# CEC1734_S0_2HW device description
Architecture: CORTEX-M4; Family: CEC173X; Series: CEC
Registers are 32-bit, read-write, reset 0x0 unless marked. A register's access mark holds for its fields unless they carry their own. Offsets are from the block's base; [hi:lo] are bit positions.

## PCR — The Power, Clocks, and Resets (PCR) Section identifies clock sources, and reset inputs to the chip.
Instances: PCR 0x40080100
0x04 PROC_CLK_CTRL reset 0x4 — Processor Clock Control Register [7:0] Processor Clock Divide Value (PROC_DIV)
  [7:0] DIV — Selects the EC clock rate
    1=DIVIDE_BY_1 (Divide 96 MHz clock by 1 (96 MHz Processor Clock)); 2=DIVIDE_BY_2 (Divide 96 MHz clock by 2 (48 MHz Processor Clock)); 4=DIVIDE_BY_4 (Divide 96 MHz clock by 4 (24 MHz Processor Clock)); 16=DIVIDE_BY_16 (Divide 96 MHz clock by 16 (6 MHz Processor Clock)); 48=DIVIDE_BY_48 (Divide 96 MHz clock by 48 (2 MHz Processor Clock))
0x08 SLOW_CLK_CTRL reset 0x1E0 — Configures the EC_CLK clock domain
  [9:0] DIV — SLOW_CLOCK_DIVIDE. n=Divide by n; 0=Clock off
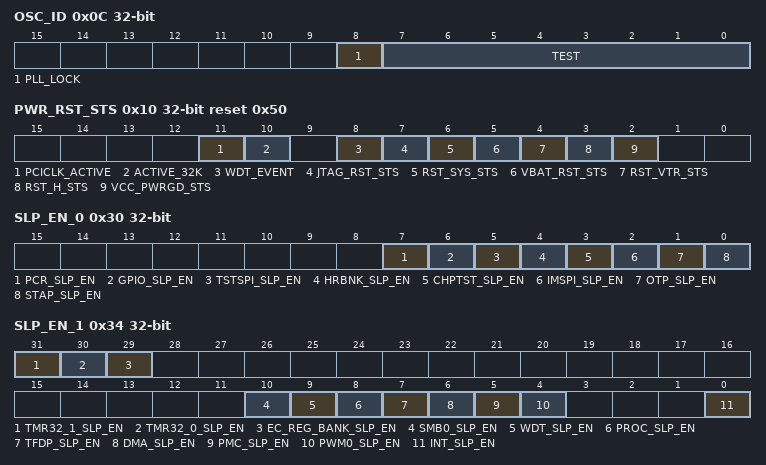
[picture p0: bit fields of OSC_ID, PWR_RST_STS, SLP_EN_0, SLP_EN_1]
0x0C OSC_ID — Oscillator ID Register
  [8] PLL_LOCK — PLL Lock Status
  [7:0] TEST — Test bits
0x10 PWR_RST_STS reset 0x50 — PCR Power Reset Status Register
  [11] PCICLK_ACTIVE — PCICLK_ACTIVE (PCICLK_ACTIVE)
  [10] ACTIVE_32K — 32K ACTIVE (ACTIVE_32K)
  [8] WDT_EVENT — Indicates that a WDT_EVENT happened. (R/W1C) 0 = Not active. 1 = A WDT_EVENT occured.
  [7] JTAG_RST_STS — Indicates status of JTAG_TRST# pin. 0 = No JTAG reset occurred since the last time this bit was cleared. 1 = A reset occurred because of a JTAG command.
  [6] RST_SYS_STS — Indicates the status of RESET_SYS.(R/W1C) 0 = No reset occurred since the last time this bit was cleared. 1 = A reset occurred.
  [5] VBAT_RST_STS — VBAT reset status 0 = No reset occurred while VTR was off or since the last time this bit was cleared. 1 = A reset occurred.(R/WC)
  [4] RST_VTR_STS — Indicates the status of RESET_VTR. 0 = reset active. 1 = reset not active.(R/W1C)
  [3] RST_H_STS — Indicates the status of RESET_VCC. 0 = reset active. 1 = reset not active.
  [2] VCC_PWRGD_STS — Indicates the status of VCC_PWRGD. 0 = PWRGD not asserted. 1 = PWRGD asserte.
0x18 SYS_RST — System Reset Register
  [8] SOFT_SYS_RST — A write of a 1 forces an assertion of the RESET_SYS reset signal, resetting the device. A write of 0 has no effect.
0x24 PRIV_EN_LOCK — Peripheral Privilege Register
  [0] LOCK_EN — Peripheral Privilege Lock Register. 1=Locked, 0=Unlocked. Locks Itself and CHIP_PRIV_EN, EC_PRIV_EN, EC_PRIV_EN2, EC_PRIV_EN3, HOST_PRIV_EN registers
0x30 SLP_EN_0 — Sleep Enable 0 Register
  [7] PCR_SLP_EN — PCR Sleep Enable
  [6] GPIO_SLP_EN — GPIO Sleep Enable
  [5] TSTSPI_SLP_EN — Test SPI Sleep Enable
  [4] HRBNK_SLP_EN — Host Register Bank Sleep Enable
  [3] CHPTST_SLP_EN — Chip Test Sleep Enable
  [2] IMSPI_SLP_EN — IMSPI Sleep Enable
  [1] OTP_SLP_EN — OTP Sleep Enable
  [0] STAP_SLP_EN — STAP Sleep Enable
0x34 SLP_EN_1 — Sleep Enable 1 Register
  [31] TMR32_1_SLP_EN — TIMER32_1 Sleep Enable (TIMER32_1_SLP_EN)
  [30] TMR32_0_SLP_EN — TIMER32_0 Sleep Enable (TIMER32_0_SLP_EN)
  [29] EC_REG_BANK_SLP_EN — EC Register Bank Sleep Enable (EC_REG_BANK_SLP_EN)
  [10] SMB0_SLP_EN — SMB0 Sleep Enable (SMB0_SLP_EN)
  [9] WDT_SLP_EN — Watch Dog Sleep Enable (WDT_SLP_EN)
  [8] PROC_SLP_EN — PROCESSOR Sleep Enable (PROCESSOR_SLP_EN)
  [7] TFDP_SLP_EN — TFDP Sleep Enable (TFDP_SLP_EN)
  [6] DMA_SLP_EN — DMA Sleep Enable (DMA_SLP_EN)
  [5] PMC_SLP_EN — PMC Sleep Enable (PMC_SLP_EN)
  [4] PWM0_SLP_EN — PWM0 Sleep Enable (PWM0_SLP_EN)
  [0] INT_SLP_EN — Interrupt Sleep Enable
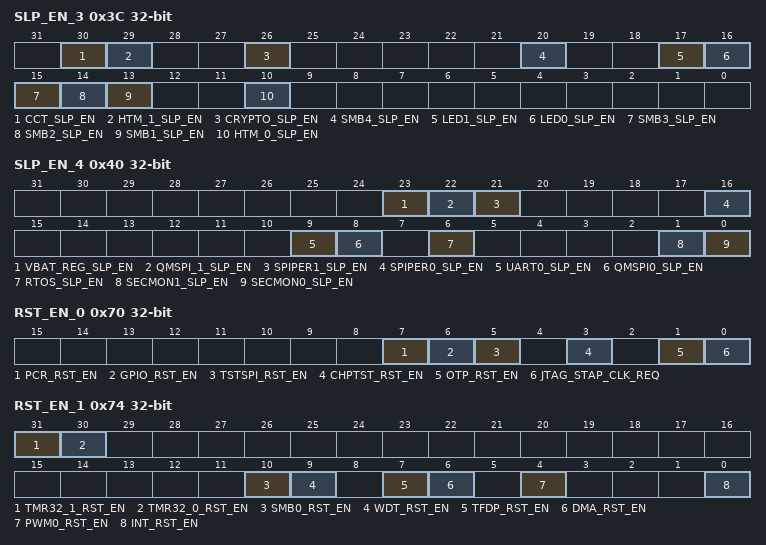
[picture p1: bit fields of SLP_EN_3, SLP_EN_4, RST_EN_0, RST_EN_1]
0x3C SLP_EN_3 — Sleep Enable 3 Register
  [30] CCT_SLP_EN — Capture Compare Timer Sleep Enable (CCTIMER_SLP_EN)
  [29] HTM_1_SLP_EN — Hibernation TIMER 1 Sleep Enable (HTM_1_SLP_EN)
  [26] CRYPTO_SLP_EN — CRYPTO Sleep Enable
  [20] SMB4_SLP_EN — SMB4 Sleep Enable (SMB4_SLP_EN)
  [17] LED1_SLP_EN — LED1 Sleep Enable (LED1_SLP_EN)
  [16] LED0_SLP_EN — LED0 Sleep Enable (LED0_SLP_EN)
  [15] SMB3_SLP_EN — SMB3 Sleep Enable (SMB3_SLP_EN)
  [14] SMB2_SLP_EN — SMB2 Sleep Enable (SMB2_SLP_EN)
  [13] SMB1_SLP_EN — SMB1 Sleep Enable (SMB1_SLP_EN)
  [10] HTM_0_SLP_EN — Hibernation Timer 0 Sleep Enable (HTM_0_SLP_EN)
0x40 SLP_EN_4 — Sleep Enable 4 Register
  [23] VBAT_REG_SLP_EN — VBAT REG Sleep Enable (VBAT_REG_SLP_EN)
  [22] QMSPI_1_SLP_EN — QMSPI 1 Sleep Enable (QMSPI_1_SLP_EN)
  [21] SPIPER1_SLP_EN — SPI Peropheral 1 Sleep Enable (SPIPER1_SLP_EN)
  [16] SPIPER0_SLP_EN — SPI Peropheral 0 Sleep Enable (SPIPER0_SLP_EN)
  [9] UART0_SLP_EN — UART0 Sleep Enable (UART_1_SLP_EN)
  [8] QMSPI0_SLP_EN — Quad Master SPI 0 Sleep Enable (QMSPI_1_SLP_EN)
  [6] RTOS_SLP_EN — RTOS Sleep Enable (RTOS_SLP_EN)
  [1] SECMON1_SLP_EN — SPI Monitor 1 Sleep Enable (SECMON1_SLP_EN)
  [0] SECMON0_SLP_EN — SPI Monitor 0 Sleep Enable (SECMON0_SLP_EN)
0x70 RST_EN_0 — Reset Enable 0 Register
  [7] PCR_RST_EN — PCR Reset Enable
  [6] GPIO_RST_EN — GPIO Reset Enable
  [5] TSTSPI_RST_EN — Test SPI Reset Enable
  [3] CHPTST_RST_EN — Chip Test Reset Enable
  [1] OTP_RST_EN — OTP Reset Enable
  [0] JTAG_STAP_CLK_REQ — JTAG STAP Enable
0x74 RST_EN_1 — Reset Enable 1 Register
  [31] TMR32_1_RST_EN — TIMER32_1 Reset Enable (TIMER32_1_RST_EN)
  [30] TMR32_0_RST_EN — TIMER32_0 Reset Enable (TIMER32_0_RST_EN)
  [10] SMB0_RST_EN — SMB0 Reset Enable (SMB0_RST_EN)
  [9] WDT_RST_EN — WDT Reset Enable (WDT_RST_EN)
  [7] TFDP_RST_EN — TFDP Reset Enable (TFDP_RST_EN)
  [6] DMA_RST_EN — DMA Reset Enable (DMA_RST_EN)
  [4] PWM0_RST_EN — PWM0 Reset Enable (PWM0_RST_EN)
  [0] INT_RST_EN — Interrupt Reset Enable
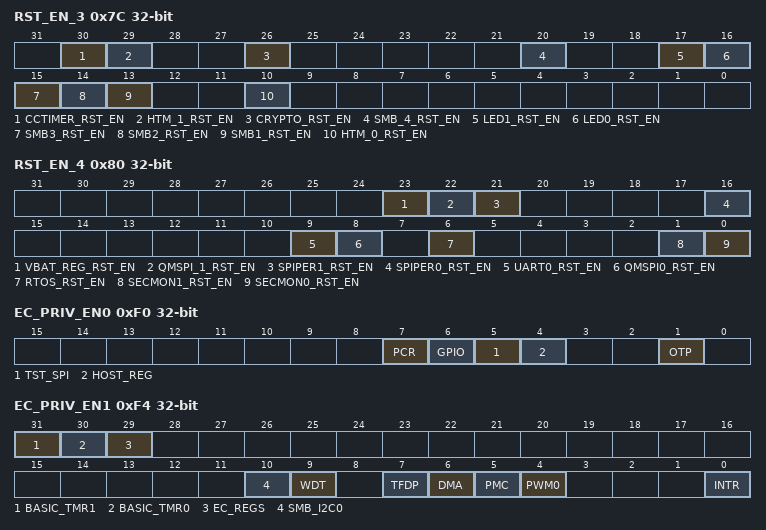
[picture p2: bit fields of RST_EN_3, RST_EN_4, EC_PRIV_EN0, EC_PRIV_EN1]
0x7C RST_EN_3 — Reset Enable 3 Register
  [30] CCTIMER_RST_EN — Capture Compare Timer Reset Enable (CCTIMER_RST_EN)
  [29] HTM_1_RST_EN — Hibernation TIMER 1 Reset Enable (HTM_1_RST_EN)
  [26] CRYPTO_RST_EN — CRYPTO Reset Enable
  [20] SMB_4_RST_EN — SMB 4 Reset Enable (SMB_4_RST_EN)
  [17] LED1_RST_EN — LED1 Reset Enable (LED1_RST_EN)
  [16] LED0_RST_EN — LED0 Reset Enable (LED0_RST_EN)
  [15] SMB3_RST_EN — SMB3 Reset Enable (SMB3_RST_EN)
  [14] SMB2_RST_EN — SMB2 Reset Enable (SMB2_RST_EN)
  [13] SMB1_RST_EN — SMB1 Reset Enable (SMB1_RST_EN)
  [10] HTM_0_RST_EN — Hibernation TIMER 0 Reset Enable (HTM_0_RST_EN)
0x80 RST_EN_4 — Reset Enable 4 Register
  [23] VBAT_REG_RST_EN — VBAT REG Reset Enable (VBAT_REG_RST_EN)
  [22] QMSPI_1_RST_EN — QMSPI 1 Reset Enable (QMSPI_1_RST_EN)
  [21] SPIPER1_RST_EN — SPI Peropheral 1 Reset Enable (SPIPER1_RST_EN)
  [16] SPIPER0_RST_EN — SPI Peropheral 0 Reset Enable (SPIPER0_RST_EN)
  [9] UART0_RST_EN — UART0 Reset Enable (UART_0_RST_EN)
  [8] QMSPI0_RST_EN — Quad Master SPI 0 Reset Enable (QMSPI_1_RST_EN)
  [6] RTOS_RST_EN — RTOS Reset Enable (RTOS_RST_EN)
  [1] SECMON1_RST_EN — SPI Monitor 1 Reset Enable (SECMON1_RST_EN)
  [0] SECMON0_RST_EN — SPI Monitor 0 Reset Enable (SECMON0_RST_EN)
0x84 PERIPH_RST_EN_LOCK reset 0xA6382D4D — Peripheral Reset Lock Register
  [31:0] EN — PCR Reset Enable Lock Register.
0xF0 EC_PRIV_EN0 — EC Priviliges 0 Register
  [7] PCR — PCR Privilege Enable.
  [6] GPIO — GPIO Privilege Enable.
  [5] TST_SPI — Test SPI Privilege Enable.
  [4] HOST_REG — Host Register Bank Privilege Enable.
  [1] OTP — OTP Privilege Enable.
0xF4 EC_PRIV_EN1 — EC Priviliges 1 Register
  [31] BASIC_TMR1 — Basic Timer 1 Privilege Enable.
  [30] BASIC_TMR0 — Basic Timer 0 Privilege Enable.
  [29] EC_REGS — EC Registers Privilege Enable.
  [10] SMB_I2C0 — SMB I2C 0 Privilege Enable.
  [9] WDT — WDT Privilege Enable.
  [7] TFDP — TFDP Privilege Enable.
  [6] DMA — DMA Privilege Enable.
  [5] PMC — PMC Privilege Enable.
  [4] PWM0 — PWM 0 Privilege Enable.
  [0] INTR — Interrupt Privilege Enable.
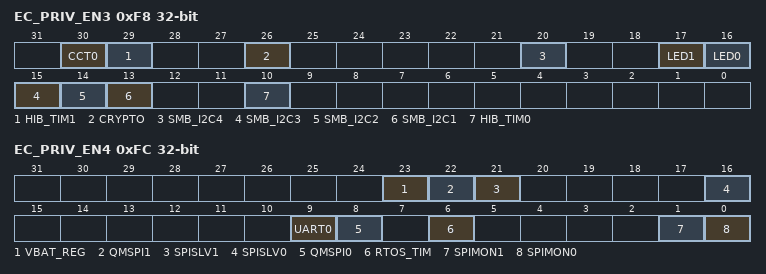
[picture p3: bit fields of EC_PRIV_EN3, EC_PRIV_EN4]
0xF8 EC_PRIV_EN3 — EC Priviliges 3 Register
  [30] CCT0 — Capture Compare Timer Privilege Enable.
  [29] HIB_TIM1 — Hibernation Timer 1 Privilege Enable.
  [26] CRYPTO — Crypto Privilege Enable.
  [20] SMB_I2C4 — SMB I2C 4 Privilege Enable.
  [17] LED1 — LED 1 Privilege Enable.
  [16] LED0 — LED 0 Privilege Enable.
  [15] SMB_I2C3 — SMB I2C 3 Privilege Enable.
  [14] SMB_I2C2 — SMB I2C 2 Privilege Enable.
  [13] SMB_I2C1 — SMB I2C 1 Privilege Enable.
  [10] HIB_TIM0 — Hibernation TIMER 0 Privilege Enable.
0xFC EC_PRIV_EN4 — EC Priviliges 4 Register
  [23] VBAT_REG — VBAT Register Privilege Enable.
  [22] QMSPI1 — QMSPI 1 Privilege Enable.
  [21] SPISLV1 — SPISLV 1 Privilege Enable.
  [16] SPISLV0 — SPISLV 0 Privilege Enable.
  [9] UART0 — UART 0 Privilege Enable.
  [8] QMSPI0 — QMSPI 0 Privilege Enable.
  [6] RTOS_TIM — RTOS Timer Privilege Enable.
  [1] SPIMON1 — SPI Monitor 1 Privilege Enable.
  [0] SPIMON0 — SPI Monitor 0 Privilege Enable.
Value list PCR_PLL_REF__PLL_REF_SRC: 0=INTERNAL_SILICON_OSC (Internal Silicon Oscillator); 2=VTR_PIN_32KHz_IN; 3=NONE_OFF
